# 3065PNPIRH register map
File version: 1.0
Registers are 32-bit, access per field, reset 0x0 unless marked. A register's access mark holds for its fields unless they carry their own. Offsets are from the block's base; [hi:lo] are bit positions.

## TSENSOR_REG — TSENSOR_REG peripheral interface
Base 0x18500000
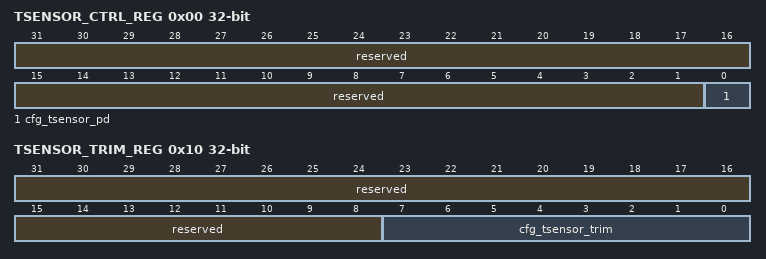
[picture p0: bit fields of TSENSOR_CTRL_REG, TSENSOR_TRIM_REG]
0x00 TSENSOR_CTRL_REG — TSENSOR_CTRL_REG为TSENSOR控制寄存器。
  [31:1] reserved ro — 保留。
  [0] cfg_tsensor_pd rw — Tsensor的关断信号。 0：使能Tsensor； 1：关断Tsensor。
0x10 TSENSOR_TRIM_REG — TSENSOR_TRIM_REG为TSENSOR TRIM寄存器。
  [31:8] reserved ro — 保留。
  [7:0] cfg_tsensor_trim rw — Tsensor trim信息。

## PGA0 — PGA0 peripheral interface
Base 0x18200000
Same registers: PGA1 0x18201000, PGA2 0x18202000
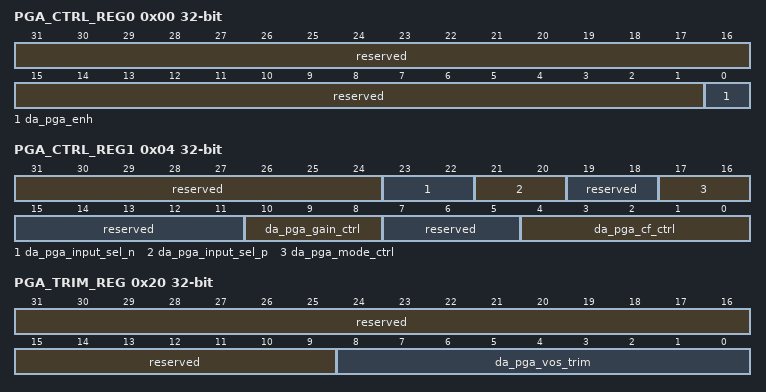
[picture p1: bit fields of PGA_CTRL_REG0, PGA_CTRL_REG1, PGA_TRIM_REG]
0x00 PGA_CTRL_REG0 — PGA_CTRL_REG0为PGA控制寄存器0。
  [31:1] reserved ro — 保留。
  [0] da_pga_enh rw — PGA使能信号。 0：关闭； 1：使能。
0x04 PGA_CTRL_REG1 — PGA_CTRL_REG1为PGA控制寄存器1。
  [31:24] reserved ro — 保留。
  [23:22] da_pga_input_sel_n rw — PGA输入N端选择。 0：N0； 1：N1； 2：N2； 3：N3。
  [21:20] da_pga_input_sel_p rw — PGA输入P端选择。 0：P0； 1：P1； 2：P2； 3：P3。
  [19:18] reserved ro — 保留。
  [17:16] da_pga_mode_ctrl rw — PGA模式配置。 0：内部电阻增益模式； 1：外部电阻增益模式。
  [15:11] reserved ro — 保留。
  [10:8] da_pga_gain_ctrl rw — PGA内部电阻增益配置。 00：x2； 01：x4； 10：x8； 11：x16。
  [7:5] reserved ro — 保留。
  [4:0] da_pga_cf_ctrl rw — PGA外部增益模式下的前馈电容补偿配置。 0：x2； 1：x3； 2：x4； 3：x5； 4：x6； 5：x7； 6：x8； 7：x9； 15：x10～x12； 23：x13~x15； 31：x16~x20。
0x20 PGA_TRIM_REG — PGA_TRIM_REG为PGA TRIM寄存器。
  [31:9] reserved ro — 保留。
  [8:0] da_pga_vos_trim rw — PGA的失调trim信息。

## DAC0 — DAC0 peripheral interface
Base 0x18400000
Same registers: DAC1 0x18401000, DAC2 0x18402000
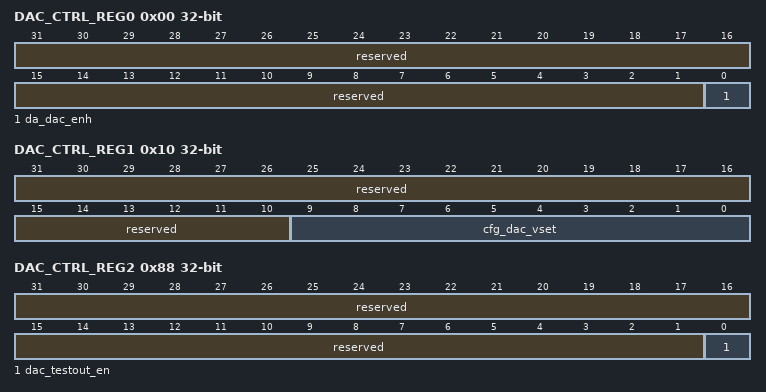
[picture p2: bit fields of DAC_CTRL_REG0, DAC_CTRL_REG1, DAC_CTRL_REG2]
0x00 DAC_CTRL_REG0 — DAC_CTRL_REG0为DAC控制寄存器0。
  [31:1] reserved ro — 保留。
  [0] da_dac_enh rw — DAC使能信号。 0：关闭； 1：使能。
0x10 DAC_CTRL_REG1 — DAC_CTRL_REG1为DAC控制寄存器1。
  [31:10] reserved ro — 保留。
  [9:0] cfg_dac_vset rw — DAC电压档位。
0x88 DAC_CTRL_REG2 — DAC_CTRL_REG2为DAC控制寄存器2。
  [31:1] reserved ro — 保留。
  [0] dac_testout_en rw — DAC输出观测使能。 0：关闭； 1：使能。

## ACMP0 — ACMP0 peripheral interface
Base 0x18300000
Same registers: ACMP1 0x18301000, ACMP2 0x18302000
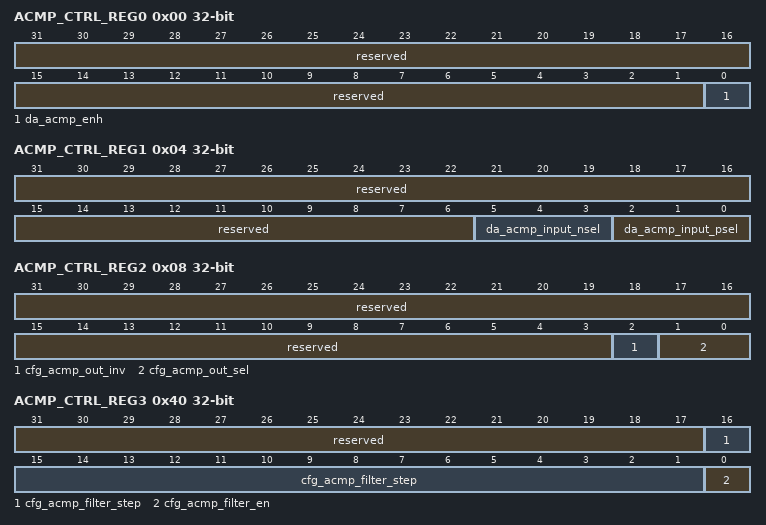
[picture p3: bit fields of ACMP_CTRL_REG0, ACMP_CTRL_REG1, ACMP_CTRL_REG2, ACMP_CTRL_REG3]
0x00 ACMP_CTRL_REG0 — ACMP_CTRL_REG0为ACMP控制寄存器0。
  [31:1] reserved ro — 保留。
  [0] da_acmp_enh rw — 比较器使能信号。 0：关闭； 1：使能。
0x04 ACMP_CTRL_REG1 — ACMP_CTRL_REG1为ACMP控制寄存器1。
  [31:6] reserved ro — 保留。
  [5:3] da_acmp_input_nsel rw — 比较器输入通道N端选通。 000：VINN0； 001：VINN1； 010：VINN2； 011：VINN3； 100：VINN4； 101：VINN5； 其他：未使用。
  [2:0] da_acmp_input_psel rw — 比较器输入通道P端选通。 000：VINP0； 001：VINP1； 010：VINP2； 011：VINP3； 100：VINP4； 101：VINP5； 其他：未使用。
0x08 ACMP_CTRL_REG2 — ACMP_CTRL_REG2为ACMP控制寄存器2。
  [31:3] reserved ro — 保留。
  [2] cfg_acmp_out_inv rw — 比较器结果极性选择。 0：结果不取反； 1：结果取反。
  [1:0] cfg_acmp_out_sel rw — 比较器输出结果选择。 00：原始比较结果； 01：滤波后结果； 10：屏蔽后结果； 11：保留。
0x40 ACMP_CTRL_REG3 — ACMP_CTRL_REG3为ACMP滤波控制寄存器。
  [31:17] reserved ro — 保留。
  [16:1] cfg_acmp_filter_step rw — 比较器滤波步长。
  [0] cfg_acmp_filter_en rw — 比较器滤波使能。 0：关闭； 1：使能。
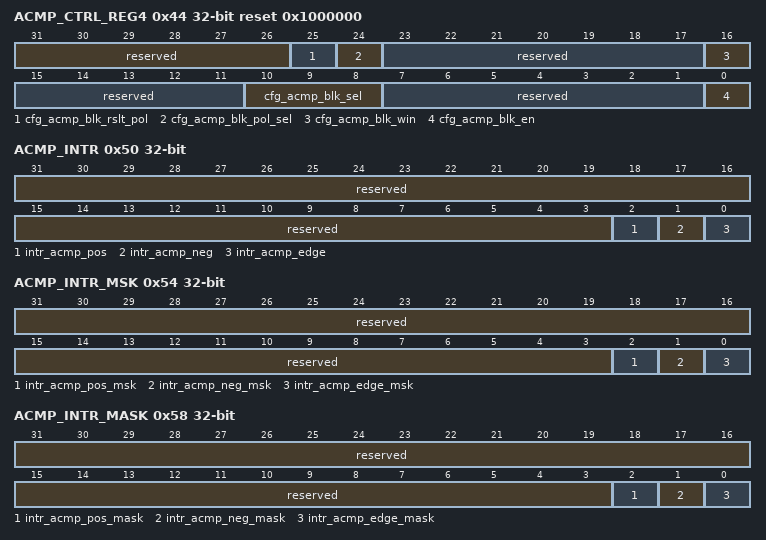
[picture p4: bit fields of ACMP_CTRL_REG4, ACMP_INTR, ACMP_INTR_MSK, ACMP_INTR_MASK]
0x44 ACMP_CTRL_REG4 reset 0x1000000 — ACMP_CTRL_REG4为ACMP屏蔽控制寄存器。
  [31:26] reserved ro — 保留。
  [25] cfg_acmp_blk_rslt_pol rw — 屏蔽结果极性选择。 0：屏蔽结果为低电平； 1：屏蔽结果为高电平。
  [24] cfg_acmp_blk_pol_sel rw — 屏蔽窗口极性选择： 0：高电平屏蔽窗有效； 1：低电平屏蔽窗有效；
  [23:17] reserved ro — 保留。
  [16] cfg_acmp_blk_win rw — 软件配置屏蔽窗口。
  [15:11] reserved ro — 保留。
  [10:8] cfg_acmp_blk_sel rw — 比较器屏蔽窗口选择。 0：软件配置屏蔽窗口； 1：APT0输出屏蔽窗口； 2：APT1输出屏蔽窗口； 3：APT2输出屏蔽窗口； 4：APT3输出屏蔽窗口； 5：APT4输出屏蔽窗口； 6：APT5输出屏蔽窗口； 7：APT6输出屏蔽窗口； 8：APT7输出屏蔽窗口； 9：APT8输出屏蔽窗口； 其他：保留。
  [7:1] reserved ro — 保留。
  [0] cfg_acmp_blk_en rw — 比较器屏蔽使能。 0：关闭； 1：使能。
0x50 ACMP_INTR access not given — ACMP_INTR为ACMP中断原始状态寄存器。
  [31:3] reserved ro — 保留。
  [2] intr_acmp_pos — 比较结果上升沿中断状态。
  [1] intr_acmp_neg — 比较结果下降沿中断状态。
  [0] intr_acmp_edge — 比较结果翻转沿中断状态。
0x54 ACMP_INTR_MSK ro — ACMP_INTR_MSK为ACMP中断屏蔽后状态寄存器。
  [31:3] reserved — 保留。
  [2] intr_acmp_pos_msk — 比较结果上升沿屏蔽后中断状态。
  [1] intr_acmp_neg_msk — 比较结果下降沿屏蔽后中断状态。
  [0] intr_acmp_edge_msk — 比较结果翻转沿屏蔽后中断状态。
0x58 ACMP_INTR_MASK — ACMP_INTR_MASK为ACMP中断屏蔽寄存器。
  [31:3] reserved ro — 保留。
  [2] intr_acmp_pos_mask rw — 比较结果上升沿中断屏蔽寄存器： 0：屏蔽中断； 1：不屏蔽。
  [1] intr_acmp_neg_mask rw — 比较结果下降沿中断屏蔽寄存器： 0：屏蔽中断； 1：不屏蔽。
  [0] intr_acmp_edge_mask rw — 比较结果翻转沿中断屏蔽寄存器： 0：屏蔽中断； 1：不屏蔽。
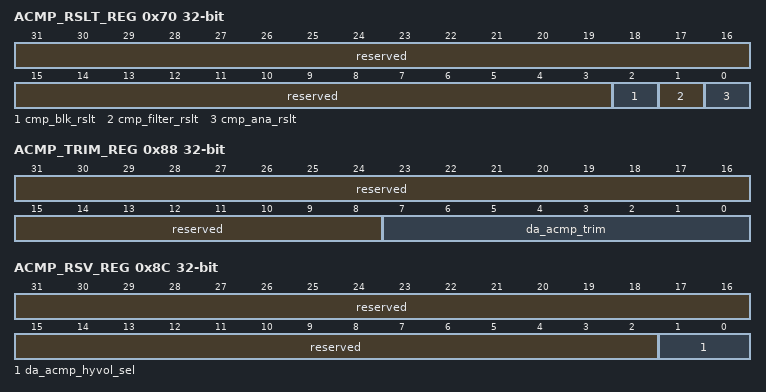
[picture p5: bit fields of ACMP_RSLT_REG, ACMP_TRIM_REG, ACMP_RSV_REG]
0x70 ACMP_RSLT_REG ro — ACMP_RSLT_REG为ACMP结果寄存器。
  [31:3] reserved — 保留。
  [2] cmp_blk_rslt — 比较器屏蔽后结果。
  [1] cmp_filter_rslt — 比较器滤波后结果。
  [0] cmp_ana_rslt — 原始比较结果。
0x88 ACMP_TRIM_REG — ACMP_TRIM_REG为ACMP TRIM寄存器。
  [31:8] reserved ro — 保留。
  [7:0] da_acmp_trim rw — ACMP TIRM寄存器。
0x8C ACMP_RSV_REG — ACMP_RSV_REG为ACMP预留寄存器。
  [31:2] reserved ro — 保留。
  [1:0] da_acmp_hyvol_sel rw — 迟滞电压选择： 00：0mV； 01：10mV； 10：20mV； 11：30mV。
